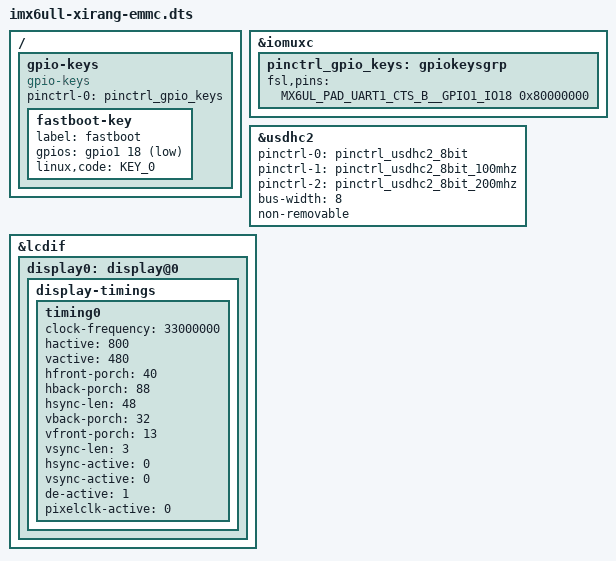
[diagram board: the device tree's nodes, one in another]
/*
 * Copyright 2019 NXP
 *
 * This program is free software; you can redistribute it and/or
 * modify it under the terms of the GNU General Public License
 * as published by the Free Software Foundation; either version 2
 * of the License, or (at your option) any later version.
 */

#include "imx6ull-14x14-evk.dts"
#include <dt-bindings/gpio/gpio.h>
#include <dt-bindings/input/input.h>

/ {
	gpio-keys {
		compatible = "gpio-keys";
		pinctrl-names = "default";
		pinctrl-0 = <&pinctrl_gpio_keys>;

		fastboot-key {
			label = "fastboot";
			gpios = <&gpio1 18 GPIO_ACTIVE_LOW>;
			linux,code = <KEY_0>;
		};
	};
};

&iomuxc {
	pinctrl_gpio_keys: gpiokeysgrp {
		fsl,pins = <
			MX6UL_PAD_UART1_CTS_B__GPIO1_IO18 0x80000000
		>;
	};
};

&usdhc2 {
	pinctrl-names = "default", "state_100mhz", "state_200mhz";
	pinctrl-0 = <&pinctrl_usdhc2_8bit>;
	pinctrl-1 = <&pinctrl_usdhc2_8bit_100mhz>;
	pinctrl-2 = <&pinctrl_usdhc2_8bit_200mhz>;
	bus-width = <8>;
	non-removable;
	status = "okay";
};

&lcdif {
	display0: display@0 {
		display-timings {
			timing0 {
				clock-frequency = <33000000>;
				hactive = <800>;
				vactive = <480>;
				hfront-porch = <40>;
				hback-porch = <88>;
				hsync-len = <48>;
				vback-porch = <32>;
				vfront-porch = <13>;
				vsync-len = <3>;

				hsync-active = <0>;
				vsync-active = <0>;
				de-active = <1>;
				pixelclk-active = <0>;
			};
		};
	};
};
